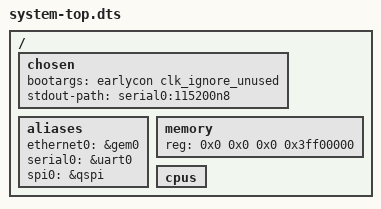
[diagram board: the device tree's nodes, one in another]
/*
 * CAUTION: This file is automatically generated by Xilinx.
 * Version:  
 * Today is: Mon Jan 25 11:18:51 2021
 */


/dts-v1/;
#include "zynqmp.dtsi"
#include "zynqmp-clk-ccf.dtsi"
#include "zcu106-reva.dtsi"
#include "pl.dtsi"
#include "pcw.dtsi"
/ {
	chosen {
		bootargs = "earlycon clk_ignore_unused";
		stdout-path = "serial0:115200n8";
	};
	aliases {
		ethernet0 = &gem0;
		serial0 = &uart0;
		spi0 = &qspi;
	};
	memory {
		device_type = "memory";
		reg = <0x0 0x0 0x0 0x3ff00000>;
	};
	cpus {
		/delete-node/ cpu@2 ;
		/delete-node/ cpu@3 ;
	};
};
#include "system-user.dtsi"
